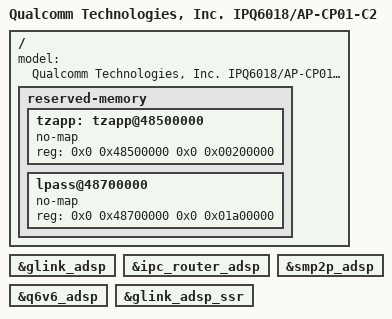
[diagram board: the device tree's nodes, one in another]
/dts-v1/;
/*
 * Copyright (c) 2019, The Linux Foundation. All rights reserved.
 *
 * Permission to use, copy, modify, and/or distribute this software for any
 * purpose with or without fee is hereby granted, provided that the above
 * copyright notice and this permission notice appear in all copies.
 *
 * THE SOFTWARE IS PROVIDED "AS IS" AND THE AUTHOR DISCLAIMS ALL WARRANTIES
 * WITH REGARD TO THIS SOFTWARE INCLUDING ALL IMPLIED WARRANTIES OF
 * MERCHANTABILITY AND FITNESS. IN NO EVENT SHALL THE AUTHOR BE LIABLE FOR
 * ANY SPECIAL, DIRECT, INDIRECT, OR CONSEQUENTIAL DAMAGES OR ANY DAMAGES
 * WHATSOEVER RESULTING FROM LOSS OF USE, DATA OR PROFITS, WHETHER IN AN
 * ACTION OF CONTRACT, NEGLIGENCE OR OTHER TORTIOUS ACTION, ARISING OUT OF
 * OR IN CONNECTION WITH THE USE OR PERFORMANCE OF THIS SOFTWARE.
 */

#include "qcom-ipq6018-cp01.dtsi"
#include "qcom-ipq6018-audio-overlay.dtsi"

/ {
	model = "Qualcomm Technologies, Inc. IPQ6018/AP-CP01-C2";

	/*
	 * +=========+==============+========================+
	 * |        |              |                         |
	 * | Region | Start Offset |          Size           |
	 * |        |              |                         |
	 * +--------+--------------+-------------------------+
	 * |        |              |                         |
	 * |        |              |                         |
	 * |        |              |                         |
	 * |        |              |                         |
	 * | Linux  |  0x41000000  |         117MB           |
	 * |        |              |                         |
	 * |        |              |                         |
	 * |        |              |                         |
	 * +--------+--------------+-------------------------+
	 * | TZ App |  0x48500000  |           2MB           |
	 * +--------+--------------+-------------------------+
	 * |        |              |                         |
	 * | LPASS  |              |                         |
	 * |   Q6   |  0x48700000  |          26MB           |
	 * |        |              |                         |
	 * +--------+--------------+-------------------------+
	 *
	 * From the available 145 MB for Linux in the first 256 MB,
	 * we are reserving 26 MB for LPASS and 2 MB for TZAPP.
	 *
	 * Refer arch/arm64/boot/dts/qcom/qcom-ipq6018-memory.dtsi
	 * for memory layout.
	 */

	reserved-memory {
		tzapp:tzapp@48500000 {	/* TZAPPS */
			no-map;
			reg = <0x0 0x48500000 0x0 0x00200000>;
		};

		lpass@48700000 {
			no-map;
			reg = <0x0 0x48700000 0x0 0x01a00000>;
		};
	};
};

&glink_adsp {
	status = "ok";
};

&ipc_router_adsp {
	status = "ok";
};

&smp2p_adsp {
	status = "ok";
};

&q6v6_adsp {
	status = "ok";
};

&glink_adsp_ssr {
	status = "ok";
};
